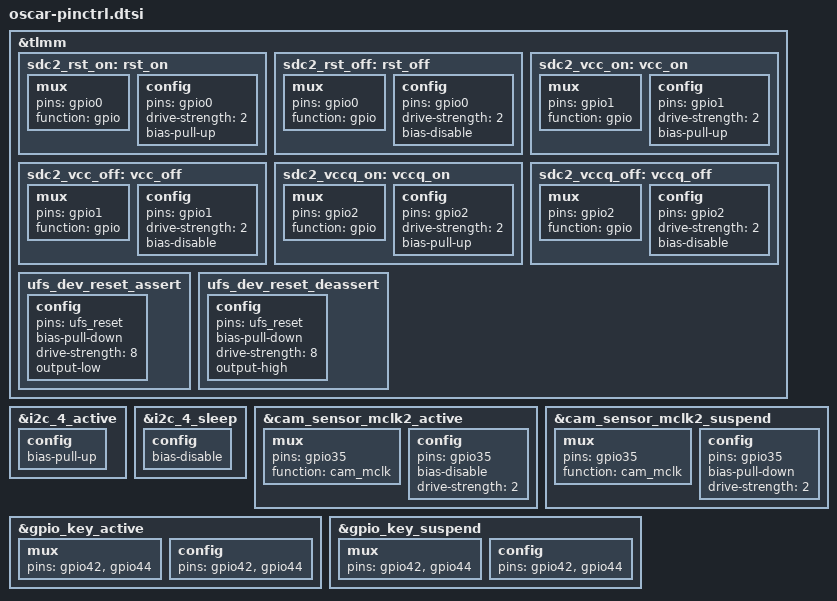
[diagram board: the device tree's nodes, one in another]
/*
 * Copyright (c) 2017, The Linux Foundation. All rights reserved.
 *
 * This program is free software; you can redistribute it and/or modify
 * it under the terms of the GNU General Public License version 2 and
 * only version 2 as published by the Free Software Foundation.
 *
 * This program is distributed in the hope that it will be useful,
 * but WITHOUT ANY WARRANTY; without even the implied warranty of
 * MERCHANTABILITY or FITNESS FOR A PARTICULAR PURPOSE.  See the
 * GNU General Public License for more details.
 */

&tlmm {
	sdc2_rst_on: rst_on {
		mux {
			pins = "gpio0";
			function = "gpio";
		};

		config {
			pins = "gpio0";
			drive-strength = <2>;
			bias-pull-up;
		};
	};

	sdc2_rst_off: rst_off {
		mux {
			pins = "gpio0";
			function = "gpio";
		};

		config {
			pins = "gpio0";
			drive-strength = <2>;
			bias-disable;
		};
	};

	sdc2_vcc_on: vcc_on {
		mux {
			pins = "gpio1";
			function = "gpio";
		};

		config {
			pins = "gpio1";
			drive-strength = <2>;
			bias-pull-up;
		};
	};

	sdc2_vcc_off: vcc_off {
		mux {
			pins = "gpio1";
			function = "gpio";
		};

		config {
			pins = "gpio1";
			drive-strength = <2>;
			bias-disable;
		};
	};

	sdc2_vccq_on: vccq_on {
		mux {
			pins = "gpio2";
			function = "gpio";
		};

		config {
			pins = "gpio2";
			drive-strength = <2>;
			bias-pull-up;
		};
	};

	sdc2_vccq_off: vccq_off {
		mux {
			pins = "gpio2";
			function = "gpio";
		};

		config {
			pins = "gpio2";
			drive-strength = <2>;
			bias-disable;
		};
	};

	ufs_dev_reset_assert: ufs_dev_reset_assert {
		config {
			pins = "ufs_reset";
			bias-pull-down;     /* default: pull down */
			/*
			 * UFS_RESET driver strengths are having
			 * different values/steps compared to typical
			 * GPIO drive strengths.
			 *
			 * Following table clarifies:
			 *
			 * HDRV value | UFS_RESET | Typical GPIO
			 *   (dec)    |   (mA)    |    (mA)
			 *     0      |   0.8     |    2
			 *     1      |   1.55    |    4
			 *     2      |   2.35    |    6
			 *     3      |   3.1     |    8
			 *     4      |   3.9     |    10
			 *     5      |   4.65    |    12
			 *     6      |   5.4     |    14
			 *     7      |   6.15    |    16
			 *
			 * POR value for UFS_RESET HDRV is 3 which means
			 * 3.1mA and we want to use that. Hence just
			 * specify 8mA to "drive-strength" binding and
			 * that should result into writing 3 to HDRV
			 * field.
			 */
			 drive-strength = <8>;   /* default: 3.1 mA */
			 output-low; /* active low reset */
		};
	};

	ufs_dev_reset_deassert: ufs_dev_reset_deassert {
		config {
			pins = "ufs_reset";
			bias-pull-down;     /* default: pull down */
			/*
			 * default: 3.1 mA
			 * check comments under ufs_dev_reset_assert
			 */
			drive-strength = <8>;
			output-high; /* active low reset */
		};
	};

	/delete-node/ cam_actuator_vaf_active;
	/delete-node/ cam_actuator_vaf_suspend;
	/delete-node/ cam_sensor_rear_active;
	/delete-node/ cam_sensor_rear_suspend;
	/delete-node/ cam_sensor_rear2_active;
	/delete-node/ cam_sensor_rear2_suspend;
	/delete-node/ cam_sensor_front_active;
	/delete-node/ cam_sensor_front_suspend;
};

&i2c_4_active {
	config {
		bias-pull-up;
	};
};

&i2c_4_sleep {
	config {
		bias-disable;
	};
};

&cam_sensor_mclk2_active {
	/* MCLK2 */
	mux {
		/* CLK, DATA */
		pins = "gpio35";
		function = "cam_mclk";
	};

	config {
		pins = "gpio35";
		bias-disable; /* No PULL */
		drive-strength = <2>; /* 2 MA */
	};
};

&cam_sensor_mclk2_suspend {
	/* MCLK2 */
	mux {
		/* CLK, DATA */
		pins = "gpio35";
		function = "cam_mclk";
	};

	config {
		pins = "gpio35";
		bias-pull-down; /* PULL DOWN */
		drive-strength = <2>; /* 2 MA */
	};
};

&gpio_key_active {
	mux {
		pins = "gpio42", "gpio44";
	};

	config {
		pins = "gpio42", "gpio44";
	};
};

&gpio_key_suspend {
	mux {
		pins = "gpio42", "gpio44";
	};

	config {
		pins = "gpio42", "gpio44";
	};
};

